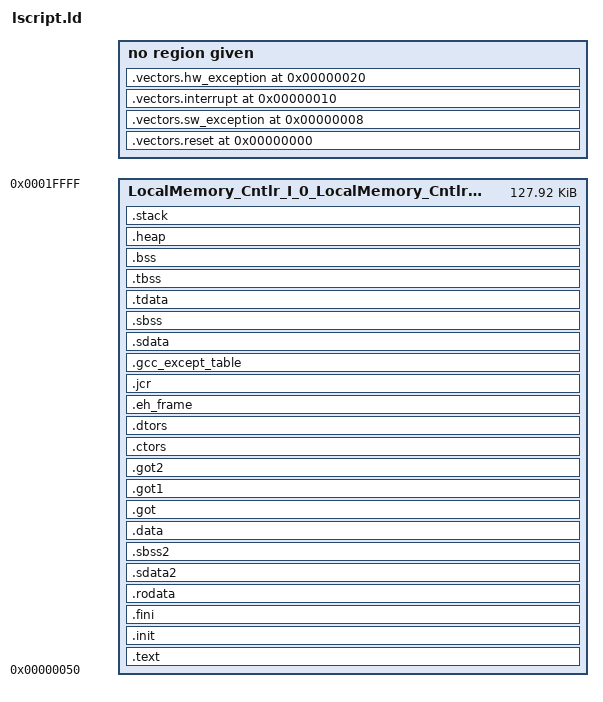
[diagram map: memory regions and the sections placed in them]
/*******************************************************************/
/*                                                                 */
/* This file is automatically generated by linker script generator.*/
/*                                                                 */
/* Version: Xilinx EDK 12.3 EDK_MS3.70d                                */
/*                                                                 */
/* Copyright (c) 2010 Xilinx, Inc.  All rights reserved.           */
/*                                                                 */
/* Description : MicroBlaze Linker Script                          */
/*                                                                 */
/*******************************************************************/

_STACK_SIZE = DEFINED(_STACK_SIZE) ? _STACK_SIZE : 0x400;
_HEAP_SIZE = DEFINED(_HEAP_SIZE) ? _HEAP_SIZE : 0x400;

/* Define Memories in the system */

MEMORY
{
   LocalMemory_Cntlr_I_0_LocalMemory_Cntlr_D_0 : ORIGIN = 0x00000050, LENGTH = 0x0001FFB0
}

/* Specify the default entry point to the program */

ENTRY(_start)

/* Define the sections, and where they are mapped in memory */

SECTIONS
{
.vectors.reset 0x00000000 : {
   *(.vectors.reset)
} 

.vectors.sw_exception 0x00000008 : {
   *(.vectors.sw_exception)
} 

.vectors.interrupt 0x00000010 : {
   *(.vectors.interrupt)
} 

.vectors.hw_exception 0x00000020 : {
   *(.vectors.hw_exception)
} 

.text : {
   *(.text)
   *(.text.*)
   *(.gnu.linkonce.t.*)
} > LocalMemory_Cntlr_I_0_LocalMemory_Cntlr_D_0

.init : {
   KEEP (*(.init))
} > LocalMemory_Cntlr_I_0_LocalMemory_Cntlr_D_0

.fini : {
   KEEP (*(.fini))
} > LocalMemory_Cntlr_I_0_LocalMemory_Cntlr_D_0

.rodata : {
   __rodata_start = .;
   *(.rodata)
   *(.rodata.*)
   *(.gnu.linkonce.r.*)
   __rodata_end = .;
} > LocalMemory_Cntlr_I_0_LocalMemory_Cntlr_D_0

.sdata2 : {
   . = ALIGN(8);
   __sdata2_start = .;
   *(.sdata2)
   *(.sdata2.*)
   *(.gnu.linkonce.s2.*)
   . = ALIGN(8);
   __sdata2_end = .;
} > LocalMemory_Cntlr_I_0_LocalMemory_Cntlr_D_0

.sbss2 : {
   __sbss2_start = .;
   *(.sbss2)
   *(.sbss2.*)
   *(.gnu.linkonce.sb2.*)
   __sbss2_end = .;
} > LocalMemory_Cntlr_I_0_LocalMemory_Cntlr_D_0

.data : {
   . = ALIGN(4);
   __data_start = .;
   *(.data)
   *(.data.*)
   *(.gnu.linkonce.d.*)
   __data_end = .;
} > LocalMemory_Cntlr_I_0_LocalMemory_Cntlr_D_0

.got : {
   *(.got)
} > LocalMemory_Cntlr_I_0_LocalMemory_Cntlr_D_0

.got1 : {
   *(.got1)
} > LocalMemory_Cntlr_I_0_LocalMemory_Cntlr_D_0

.got2 : {
   *(.got2)
} > LocalMemory_Cntlr_I_0_LocalMemory_Cntlr_D_0

.ctors : {
   __CTOR_LIST__ = .;
   ___CTORS_LIST___ = .;
   KEEP (*crtbegin.o(.ctors))
   KEEP (*(EXCLUDE_FILE(*crtend.o) .ctors))
   KEEP (*(SORT(.ctors.*)))
   KEEP (*(.ctors))
   __CTOR_END__ = .;
   ___CTORS_END___ = .;
} > LocalMemory_Cntlr_I_0_LocalMemory_Cntlr_D_0

.dtors : {
   __DTOR_LIST__ = .;
   ___DTORS_LIST___ = .;
   KEEP (*crtbegin.o(.dtors))
   KEEP (*(EXCLUDE_FILE(*crtend.o) .dtors))
   KEEP (*(SORT(.dtors.*)))
   KEEP (*(.dtors))
   __DTOR_END__ = .;
   ___DTORS_END___ = .;
} > LocalMemory_Cntlr_I_0_LocalMemory_Cntlr_D_0

.eh_frame : {
   *(.eh_frame)
} > LocalMemory_Cntlr_I_0_LocalMemory_Cntlr_D_0

.jcr : {
   *(.jcr)
} > LocalMemory_Cntlr_I_0_LocalMemory_Cntlr_D_0

.gcc_except_table : {
   *(.gcc_except_table)
} > LocalMemory_Cntlr_I_0_LocalMemory_Cntlr_D_0

.sdata : {
   . = ALIGN(8);
   __sdata_start = .;
   *(.sdata)
   *(.sdata.*)
   *(.gnu.linkonce.s.*)
   __sdata_end = .;
} > LocalMemory_Cntlr_I_0_LocalMemory_Cntlr_D_0

.sbss : {
   . = ALIGN(4);
   __sbss_start = .;
   *(.sbss)
   *(.sbss.*)
   *(.gnu.linkonce.sb.*)
   . = ALIGN(8);
   __sbss_end = .;
} > LocalMemory_Cntlr_I_0_LocalMemory_Cntlr_D_0

.tdata : {
   __tdata_start = .;
   *(.tdata)
   *(.tdata.*)
   *(.gnu.linkonce.td.*)
   __tdata_end = .;
} > LocalMemory_Cntlr_I_0_LocalMemory_Cntlr_D_0

.tbss : {
   __tbss_start = .;
   *(.tbss)
   *(.tbss.*)
   *(.gnu.linkonce.tb.*)
   __tbss_end = .;
} > LocalMemory_Cntlr_I_0_LocalMemory_Cntlr_D_0

.bss : {
   . = ALIGN(4);
   __bss_start = .;
   *(.bss)
   *(.bss.*)
   *(.gnu.linkonce.b.*)
   *(COMMON)
   . = ALIGN(4);
   __bss_end = .;
} > LocalMemory_Cntlr_I_0_LocalMemory_Cntlr_D_0

_SDA_BASE_ = __sdata_start + ((__sbss_end - __sdata_start) / 2 );

_SDA2_BASE_ = __sdata2_start + ((__sbss2_end - __sdata2_start) / 2 );

/* Generate Stack and Heap definitions */

.heap : {
   . = ALIGN(8);
   _heap = .;
   _heap_start = .;
   . += _HEAP_SIZE;
   _heap_end = .;
} > LocalMemory_Cntlr_I_0_LocalMemory_Cntlr_D_0

.stack : {
   _stack_end = .;
   . += _STACK_SIZE;
   . = ALIGN(8);
   _stack = .;
   __stack = _stack;
} > LocalMemory_Cntlr_I_0_LocalMemory_Cntlr_D_0

_end = .;
}

